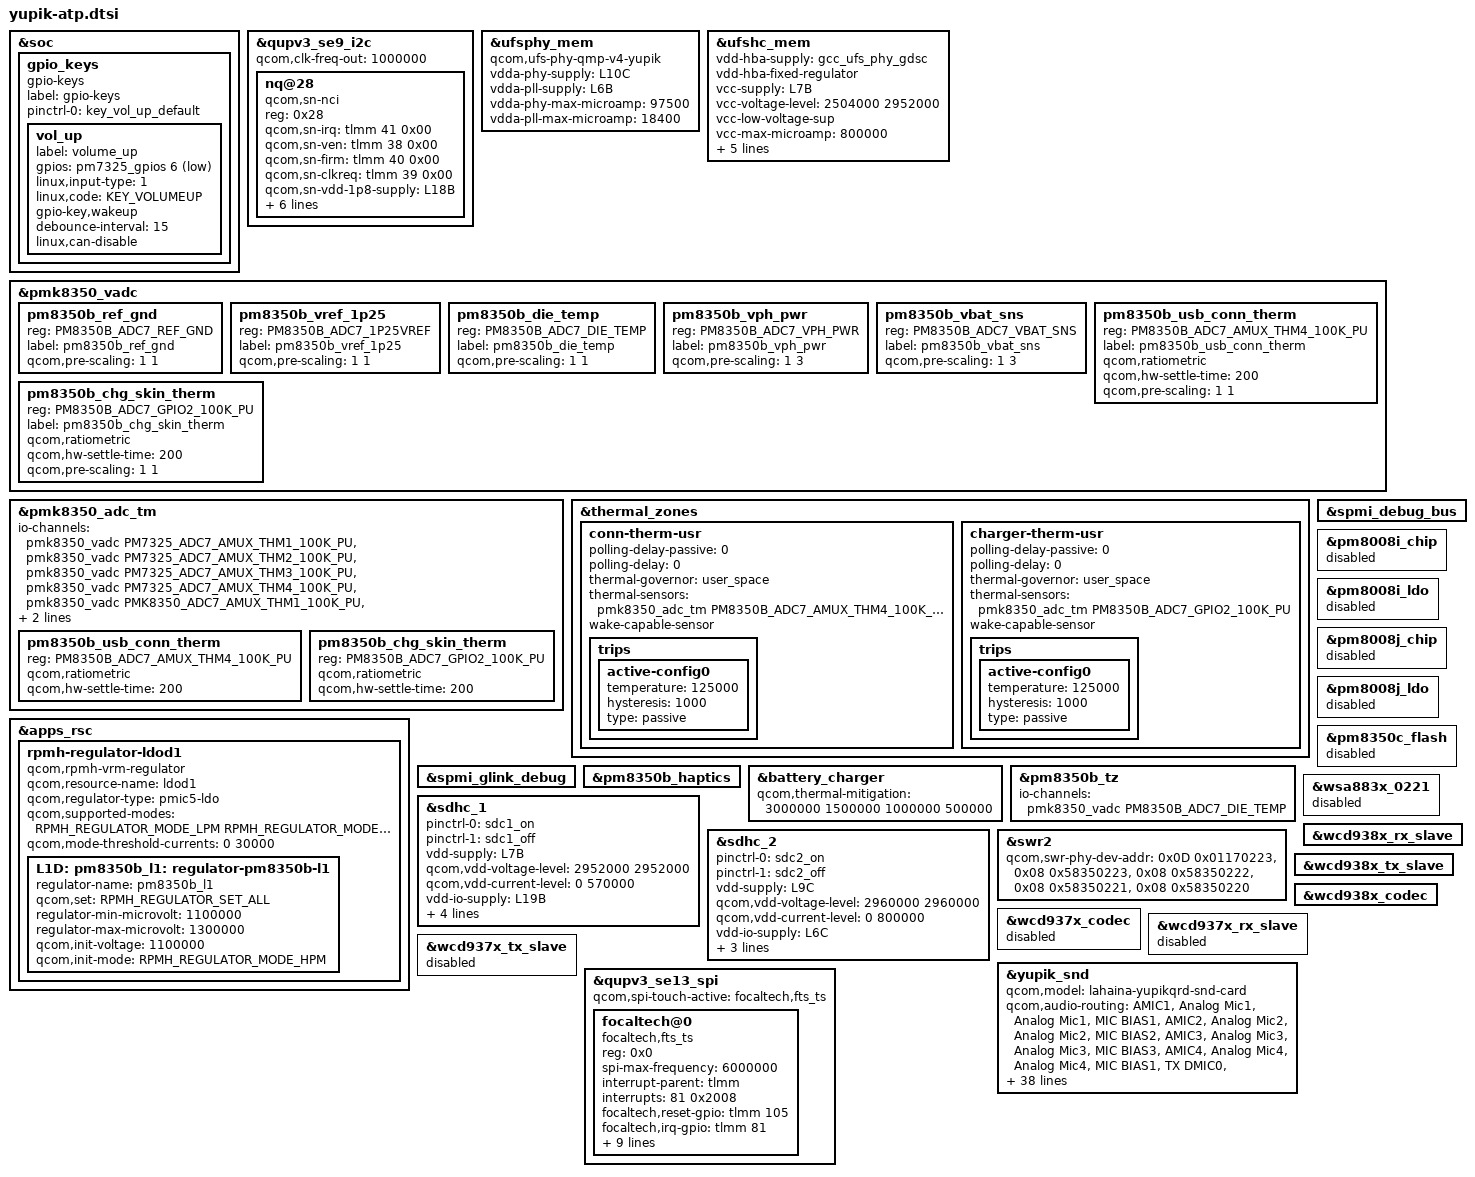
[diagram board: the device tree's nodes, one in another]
#include <dt-bindings/gpio/gpio.h>
#include <dt-bindings/regulator/qcom,rpmh-regulator-levels.h>
#include "yupik-pmic-overlay.dtsi"
#include "pm8350b.dtsi"
#include "yupik-audio-overlay.dtsi"
#include "yupik-thermal-overlay-qrd.dtsi"
#include "display/yupik-sde-display-qrd.dtsi"

&soc {
	gpio_keys {
		compatible = "gpio-keys";
		label = "gpio-keys";

		pinctrl-names = "default";
		pinctrl-0 = <&key_vol_up_default>;

		vol_up {
			label = "volume_up";
			gpios = <&pm7325_gpios 6 GPIO_ACTIVE_LOW>;
			linux,input-type = <1>;
			linux,code = <KEY_VOLUMEUP>;
			gpio-key,wakeup;
			debounce-interval = <15>;
			linux,can-disable;
		};
	};
};

&qupv3_se9_i2c {
	status = "ok";
	qcom,clk-freq-out = <1000000>;
	#address-cells = <1>;
	#size-cells = <0>;
	nq@28 {
		compatible = "qcom,sn-nci";
		reg = <0x28>;
		qcom,sn-irq = <&tlmm 41 0x00>;
		qcom,sn-ven = <&tlmm 38 0x00>;
		qcom,sn-firm = <&tlmm 40 0x00>;
		qcom,sn-clkreq = <&tlmm 39 0x00>;
		qcom,sn-vdd-1p8-supply = <&L18B>;
		qcom,sn-vdd-1p8-voltage = <1800000 1800000>;
		qcom,sn-vdd-1p8-current = <157000>;
		interrupt-parent = <&tlmm>;
		interrupts = <41 0>;
		interrupt-names = "nfc_irq";
		pinctrl-names = "nfc_active", "nfc_suspend";
		pinctrl-0 = <&nfc_int_active &nfc_enable_active>;
		pinctrl-1 = <&nfc_int_suspend &nfc_enable_suspend>;
	};
};

&ufsphy_mem {
	compatible = "qcom,ufs-phy-qmp-v4-yupik";

	vdda-phy-supply = <&L10C>;
	vdda-pll-supply = <&L6B>;
	vdda-phy-max-microamp = <97500>;
	vdda-pll-max-microamp = <18400>;

	status = "ok";
};

&ufshc_mem {
	vdd-hba-supply = <&gcc_ufs_phy_gdsc>;
	vdd-hba-fixed-regulator;

	vcc-supply = <&L7B>;
	vcc-voltage-level = <2504000 2952000>;
	vcc-low-voltage-sup;
	vcc-max-microamp = <800000>;

	/*
	 * Yupik target supports both UFS2.2 & UFS3.1, here
	 * vccq2 is supplied via eLDO, and that is controlled via
	 * L9B which supports a max voltage of 1.2V, but eLDO would
	 * supply 1.8V. and same L9B acts as vccq voltage for UFS3.1
	 * devices.
	 * Here L9B can max support for 1.2V but UFS GKI driver code
	 * votes for 1.8V, which is leading to failure from pmic
	 * regulator.
	 *
	 * Now since vccq and control of eLDO are common that is L9B
	 * we can use vccq vote as control of eLDO for vccq2.
	 * Hence vccq entries shall be used for both type of UFS
	 * devices only. And vccq entries should not be changed/removed
	 * for any design alteration.
	 */
	vccq-supply = <&L9B>;
	vccq-max-microamp = <900000>;
	vccq-min-microamp = <10000>;

	qcom,vddp-ref-clk-supply = <&L9B>;
	qcom,vddp-ref-clk-max-microamp = <100>;

	status = "ok";
};

&pmk8350_vadc {
	pm8350b_ref_gnd {
		reg = <PM8350B_ADC7_REF_GND>;
		label = "pm8350b_ref_gnd";
		qcom,pre-scaling = <1 1>;
	};

	pm8350b_vref_1p25 {
		reg = <PM8350B_ADC7_1P25VREF>;
		label = "pm8350b_vref_1p25";
		qcom,pre-scaling = <1 1>;
	};

	pm8350b_die_temp {
		reg = <PM8350B_ADC7_DIE_TEMP>;
		label = "pm8350b_die_temp";
		qcom,pre-scaling = <1 1>;
	};

	pm8350b_vph_pwr {
		reg = <PM8350B_ADC7_VPH_PWR>;
		label = "pm8350b_vph_pwr";
		qcom,pre-scaling = <1 3>;
	};

	pm8350b_vbat_sns {
		reg = <PM8350B_ADC7_VBAT_SNS>;
		label = "pm8350b_vbat_sns";
		qcom,pre-scaling = <1 3>;
	};

	pm8350b_usb_conn_therm {
		reg = <PM8350B_ADC7_AMUX_THM4_100K_PU>;
		label = "pm8350b_usb_conn_therm";
		qcom,ratiometric;
		qcom,hw-settle-time = <200>;
		qcom,pre-scaling = <1 1>;
	};

	pm8350b_chg_skin_therm {
		reg = <PM8350B_ADC7_GPIO2_100K_PU>;
		label = "pm8350b_chg_skin_therm";
		qcom,ratiometric;
		qcom,hw-settle-time = <200>;
		qcom,pre-scaling = <1 1>;
	};
};

&pmk8350_adc_tm {
	io-channels = <&pmk8350_vadc PM7325_ADC7_AMUX_THM1_100K_PU>,
			<&pmk8350_vadc PM7325_ADC7_AMUX_THM2_100K_PU>,
			<&pmk8350_vadc PM7325_ADC7_AMUX_THM3_100K_PU>,
			<&pmk8350_vadc PM7325_ADC7_AMUX_THM4_100K_PU>,
			<&pmk8350_vadc PMK8350_ADC7_AMUX_THM1_100K_PU>,
			<&pmk8350_vadc PM8350B_ADC7_AMUX_THM4_100K_PU>,
			<&pmk8350_vadc PM8350B_ADC7_GPIO2_100K_PU>;

	pm8350b_usb_conn_therm {
		reg = <PM8350B_ADC7_AMUX_THM4_100K_PU>;
		qcom,ratiometric;
		qcom,hw-settle-time = <200>;
	};

	pm8350b_chg_skin_therm {
		reg = <PM8350B_ADC7_GPIO2_100K_PU>;
		qcom,ratiometric;
		qcom,hw-settle-time = <200>;
	};
};

&thermal_zones {
	conn-therm-usr {
		polling-delay-passive = <0>;
		polling-delay = <0>;
		thermal-governor = "user_space";
		thermal-sensors = <&pmk8350_adc_tm PM8350B_ADC7_AMUX_THM4_100K_PU>;
		wake-capable-sensor;
		trips {
			active-config0 {
				temperature = <125000>;
				hysteresis = <1000>;
				type = "passive";
			};
		};
	};

	charger-therm-usr {
		polling-delay-passive = <0>;
		polling-delay = <0>;
		thermal-governor = "user_space";
		thermal-sensors = <&pmk8350_adc_tm PM8350B_ADC7_GPIO2_100K_PU>;
		wake-capable-sensor;
		trips {
			active-config0 {
				temperature = <125000>;
				hysteresis = <1000>;
				type = "passive";
			};
		};
	};
};

&apps_rsc {
	rpmh-regulator-ldod1 {
		compatible = "qcom,rpmh-vrm-regulator";
		qcom,resource-name = "ldod1";
		qcom,regulator-type = "pmic5-ldo";
		qcom,supported-modes =
			<RPMH_REGULATOR_MODE_LPM
			RPMH_REGULATOR_MODE_HPM>;
		qcom,mode-threshold-currents = <0 30000>;
		L1D:
		pm8350b_l1: regulator-pm8350b-l1 {
			regulator-name = "pm8350b_l1";
			qcom,set = <RPMH_REGULATOR_SET_ALL>;
			regulator-min-microvolt = <1100000>;
			regulator-max-microvolt = <1300000>;
			qcom,init-voltage = <1100000>;
			qcom,init-mode = <RPMH_REGULATOR_MODE_HPM>;
		};
	};
};

&spmi_debug_bus {
	status = "ok";
};

&spmi_glink_debug {
	status = "ok";
};

&pm8350b_haptics {
	status = "ok";
};

&battery_charger {
	qcom,thermal-mitigation = <3000000 1500000 1000000 500000>;
};

&pm8350b_tz {
	io-channels = <&pmk8350_vadc PM8350B_ADC7_DIE_TEMP>;
	io-channel-names = "thermal";
};

&pm8008i_chip {
	status = "disabled";
};

&pm8008i_ldo {
	status = "disabled";
};

&pm8008j_chip {
	status = "disabled";
};

&pm8008j_ldo {
	status = "disabled";
};

&pm8350c_flash {
	status = "disabled";
};

&sdhc_1 {
	pinctrl-names = "default", "sleep";
	pinctrl-0 = <&sdc1_on>;
	pinctrl-1 = <&sdc1_off>;

	vdd-supply = <&L7B>;
	qcom,vdd-voltage-level = <2952000 2952000>;
	qcom,vdd-current-level = <0 570000>;

	vdd-io-supply = <&L19B>;
	qcom,vdd-io-always-on;
	qcom,vdd-io-lpm-sup;
	qcom,vdd-io-voltage-level = <1800000 1800000>;
	qcom,vdd-io-current-level = <0 325000>;

	status = "ok";
};

&sdhc_2 {
	pinctrl-names = "default", "sleep";
	pinctrl-0 = <&sdc2_on>;
	pinctrl-1 = <&sdc2_off>;

	vdd-supply = <&L9C>;
	qcom,vdd-voltage-level = <2960000 2960000>;
	qcom,vdd-current-level = <0 800000>;

	vdd-io-supply = <&L6C>;
	qcom,vdd-io-voltage-level = <1800000 2960000>;
	qcom,vdd-io-current-level = <0 22000>;

	cd-gpios = <&tlmm 91 GPIO_ACTIVE_LOW>;

	status = "ok";
};

&wsa883x_0221 {
	status = "disabled";
};

&swr2 {
	qcom,swr-phy-dev-addr = <0x0D 0x01170223>,
				<0x08 0x58350223>,
				<0x08 0x58350222>,
				<0x08 0x58350221>,
				<0x08 0x58350220>;
};

&wcd938x_rx_slave {
	status = "okay";
};

&wcd938x_tx_slave {
	status = "okay";
};

&wcd938x_codec {
	status = "okay";
};

&wcd937x_codec {
	status = "disabled";
};

&wcd937x_rx_slave {
	status = "disabled";
};

&wcd937x_tx_slave {
	status = "disabled";
};

&yupik_snd {
	qcom,model = "lahaina-yupikqrd-snd-card";
	qcom,audio-routing =
		"AMIC1", "Analog Mic1",
		"Analog Mic1", "MIC BIAS1",
		"AMIC2", "Analog Mic2",
		"Analog Mic2", "MIC BIAS2",
		"AMIC3", "Analog Mic3",
		"Analog Mic3", "MIC BIAS3",
		"AMIC4", "Analog Mic4",
		"Analog Mic4", "MIC BIAS1",
		"TX DMIC0", "Digital Mic0",
		"Digital Mic0", "MIC BIAS1",
		"TX DMIC1", "Digital Mic1",
		"Digital Mic1", "MIC BIAS1",
		"TX DMIC2", "Digital Mic2",
		"Digital Mic2", "MIC BIAS3",
		"TX DMIC3", "Digital Mic3",
		"Digital Mic3", "MIC BIAS3",
		"TX DMIC4", "Digital Mic4",
		"Digital Mic4", "MIC BIAS4",
		"TX DMIC5", "Digital Mic5",
		"Digital Mic5", "MIC BIAS4",
		"IN1_HPHL", "HPHL_OUT",
		"IN2_HPHR", "HPHR_OUT",
		"IN3_AUX", "AUX_OUT",
		"WSA SRC0_INP", "SRC0",
		"WSA_TX DEC0_INP", "TX DEC0 MUX",
		"WSA_TX DEC1_INP", "TX DEC1 MUX",
		"RX_TX DEC0_INP", "TX DEC0 MUX",
		"RX_TX DEC1_INP", "TX DEC1 MUX",
		"RX_TX DEC2_INP", "TX DEC2 MUX",
		"RX_TX DEC3_INP", "TX DEC3 MUX",
		"SpkrRight IN", "WSA_SPK2 OUT",
		"TX SWR_INPUT", "WCD_TX_OUTPUT",
		"VA SWR_INPUT", "VA_SWR_CLK",
		"VA SWR_INPUT", "WCD_TX_OUTPUT",
		"VA_AIF1 CAP", "VA_SWR_CLK",
		"VA_AIF2 CAP", "VA_SWR_CLK",
		"VA_AIF3 CAP", "VA_SWR_CLK",
		"VA DMIC0", "Digital Mic0",
		"VA DMIC1", "Digital Mic1",
		"VA DMIC2", "Digital Mic2",
		"VA DMIC3", "Digital Mic3",
		"VA DMIC4", "Digital Mic4",
		"VA DMIC5", "Digital Mic5",
		"VA DMIC0", "VA MIC BIAS1",
		"VA DMIC1", "VA MIC BIAS3",
		"VA DMIC2", "VA MIC BIAS4",
		"VA DMIC3", "VA MIC BIAS1",
		"VA DMIC4", "VA MIC BIAS3",
		"VA DMIC5", "VA MIC BIAS4";
	qcom,swr-dmic-max-devs = <0>;

	qcom,msm-mbhc-hphl-swh = <1>;
	qcom,msm-mbhc-gnd-swh = <1>;

	asoc-codec  = <&stub_codec>, <&bolero>,
		      <&wcd938x_codec>,
		      <&wsa883x_0222>,
		      <&ext_disp_audio_codec>;
	asoc-codec-names = "msm-stub-codec.1", "bolero_codec",
			   "wcd938x_codec",
			   "wsa-codec2",
			   "msm-ext-disp-audio-codec-rx";
	qcom,wsa-max-devs = <1>;
	qcom,msm_audio_ssr_devs = <&audio_apr>, <&q6core>, <&lpi_tlmm>,
				  <&bolero>;
};

&qupv3_se13_spi {
	status = "ok";
	qcom,spi-touch-active = "focaltech,fts_ts";

	focaltech@0 {
		compatible = "focaltech,fts_ts";
		reg = <0x0>;
		spi-max-frequency = <6000000>;
		interrupt-parent = <&tlmm>;
		interrupts = <81 0x2008>;
		focaltech,reset-gpio = <&tlmm 105 0x00>;
		focaltech,irq-gpio = <&tlmm 81 0x2008>;
		focaltech,display-coords = <0 0 1080 2340>;
		focaltech,max-touch-number = <5>;
		focaltech,ic-type = <0x3658D488>;

		vdd-supply = <&L3C>;

		pinctrl-names = "pmx_ts_active", "pmx_ts_suspend","pmx_ts_release";
		pinctrl-0 = <&ts_active>;
		pinctrl-1 = <&ts_int_suspend &ts_reset_suspend>;
		pinctrl-2 = <&ts_release>;
		panel = <&dsi_r66451_amoled_144hz_cmd_cphy &dsi_r66451_amoled_90hz_cmd_cphy>;
	};
};
